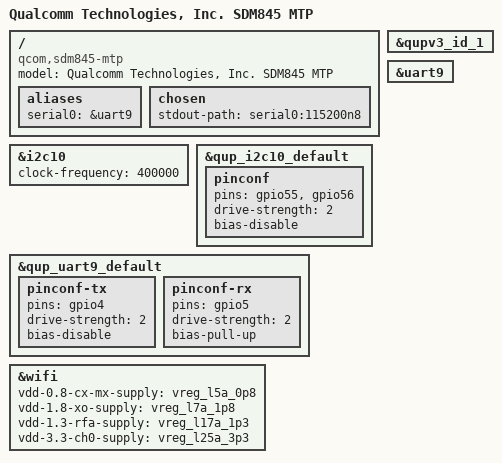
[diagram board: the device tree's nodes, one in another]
// SPDX-License-Identifier: GPL-2.0
/*
 * SDM845 MTP board device tree source
 *
 * Copyright (c) 2018, The Linux Foundation. All rights reserved.
 */

/dts-v1/;

#include "sdm845.dtsi"

/ {
	model = "Qualcomm Technologies, Inc. SDM845 MTP";
	compatible = "qcom,sdm845-mtp";

	aliases {
		serial0 = &uart9;
	};

	chosen {
		stdout-path = "serial0:115200n8";
	};
};

&i2c10 {
	status = "okay";
	clock-frequency = <400000>;
};

&qupv3_id_1 {
	status = "okay";
};

&uart9 {
	status = "okay";
};

/* PINCTRL - additions to nodes defined in sdm845.dtsi */

&qup_i2c10_default {
	pinconf {
		pins = "gpio55", "gpio56";
		drive-strength = <2>;
		bias-disable;
	};
};

&qup_uart9_default {
	pinconf-tx {
		pins = "gpio4";
		drive-strength = <2>;
		bias-disable;
	};

	pinconf-rx {
		pins = "gpio5";
		drive-strength = <2>;
		bias-pull-up;
	};
};

&wifi {
	vdd-0.8-cx-mx-supply = <&vreg_l5a_0p8>;
	vdd-1.8-xo-supply = <&vreg_l7a_1p8>;
	vdd-1.3-rfa-supply = <&vreg_l17a_1p3>;
	vdd-3.3-ch0-supply = <&vreg_l25a_3p3>;
};
